# STM32G544 register map
File version: 2.0.0
CPU: CM33 r0p4, little endian, MPU, FPU, 4 interrupt priority bits
Registers are 32-bit, read-write, reset 0x0 unless marked. A register's access mark holds for its fields unless they carry their own. Offsets are from the block's base; [hi:lo] are bit positions; lines under a group give offsets from that group; {n}, {i} and the like mark numbered series.

## I3C1 (part 2 of 2) — Improved inter-integrated circuit
Base 0x40005C00
Same registers: I3C1_S 0x50005C00
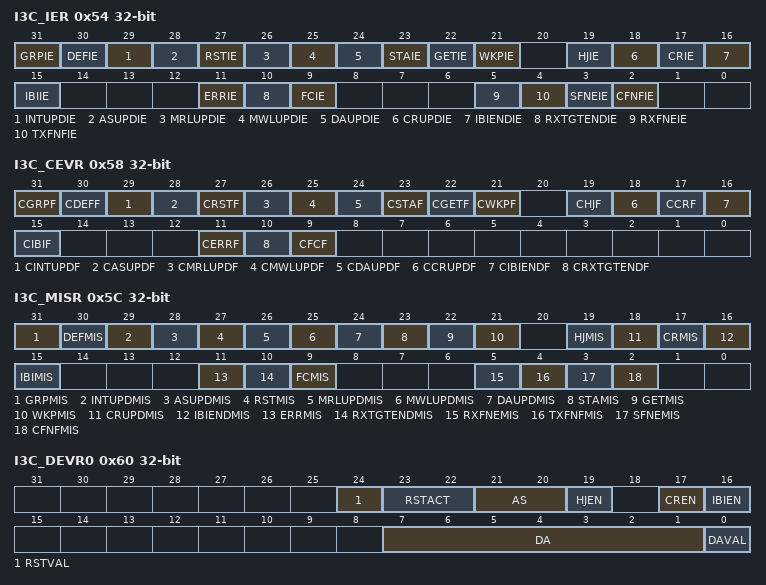
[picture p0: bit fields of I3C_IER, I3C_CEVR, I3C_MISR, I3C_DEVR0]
0x54 I3C_IER — I3C interrupt enable register
  [all] fields
    0=interrupt disabled; 1=interrupt enabled
  [31] GRPIE — DEFGRPA CCC interrupt enable (when the I3C is acting as target)
  [30] DEFIE — DEFTGTS CCC interrupt enable (when the I3C is acting as target)
  [29] INTUPDIE — ENEC/DISEC CCC interrupt enable (when the I3C is acting as target)
  [28] ASUPDIE — ENTASx CCC interrupt enable (when the I3C is acting as target)
  [27] RSTIE — reset pattern interrupt enable (when the I3C is acting as target)
  [26] MRLUPDIE — SETMRL CCC interrupt enable (when the I3C is acting as target)
  [25] MWLUPDIE — SETMWL CCC interrupt enable (when the I3C is acting as target)
  [24] DAUPDIE — ENTDAA/RSTDAA/SETNEWDA CCC interrupt enable (when the I3C is acting as target)
  [23] STAIE — GETSTATUS CCC interrupt enable (when the I3C is acting as target)
  [22] GETIE — GETxxx CCC interrupt enable (when the I3C is acting as target)
  [21] WKPIE — wakeup interrupt enable (when the I3C is acting as target)
  [19] HJIE — hot-join interrupt enable (when the I3C is acting as controller)
  [18] CRUPDIE — controller-role update interrupt enable (when the I3C is acting as target)
  [17] CRIE — controller-role request interrupt enable (when the I3C is acting as controller)
  [16] IBIENDIE — IBI end interrupt enable (when the I3C is acting as target)
  [15] IBIIE — IBI request interrupt enable (when the I3C is acting as controller)
  [11] ERRIE — error interrupt enable (whatever the I3C is acting as controller/target)
  [10] RXTGTENDIE — target-initiated read end interrupt enable (when the I3C is acting as controller)
  [9] FCIE — frame complete interrupt enable (whatever the I3C is acting as controller/target)
  [5] RXFNEIE — RX-FIFO not empty interrupt enable (whatever the I3C is acting as controller/target)
  [4] TXFNFIE — TX-FIFO not full interrupt enable (whatever the I3C is acting as controller/target)
  [3] SFNEIE — S-FIFO not empty interrupt enable (whatever the I3C is acting as controller/target)
  [2] CFNFIE — C-FIFO not full interrupt enable (whatever the I3C is acting as controller/target)
0x58 I3C_CEVR wo — I3C clear event register
  [31] CGRPF — clear DEFGRPA CCC flag (when the I3C is acting as target)
    0=no effect; 1=clear I3C_EVR.GRPF
  [30] CDEFF — clear DEFTGTS CCC flag (when the I3C is acting as target)
    0=no effect; 1=clear I3C_EVR.DEFF
  [29] CINTUPDF — clear ENEC/DISEC CCC flag (when the I3C is acting as target)
    0=no effect; 1=clear I3C_EVR.CINTUPDF
  [28] CASUPDF — clear ENTASx CCC flag (when the I3C is acting as target)
    0=no effect; 1=clear I3C_EVR.ASUPDF
  [27] CRSTF — clear reset pattern flag (when the I3C is acting as target)
    0=no effect; 1=clear I3C_EVR.RSTF
  [26] CMRLUPDF — clear SETMRL CCC flag (when the I3C is acting as target)
    0=no effect; 1=clear I3C_EVR.MRLUPDF
  [25] CMWLUPDF — clear SETMWL CCC flag (when the I3C is acting as target)
    0=no effect; 1=clear I3C_EVR.MWLUPDF
  [24] CDAUPDF — clear ENTDAA/RSTDAA/SETNEWDA CCC flag (when the I3C is acting as target)
    0=no effect; 1=clear I3C_EVR.DAUPDF
  [23] CSTAF — clear GETSTATUS CCC flag (when the I3C is acting as target)
    0=no effect; 1=clear I3C_EVR.STAF
  [22] CGETF — clear GETxxx CCC flag (when the I3C is acting as target)
    0=no effect; 1=clear I3C_EVR.GETF
  [21] CWKPF — clear wakeup flag (when the I3C is acting as target)
    0=no effect; 1=clear I3C_EVR.WKPF
  [19] CHJF — clear hot-join flag (when the I3C is acting as controller)
    0=no effect; 1=clear I3C_EVR.HJF
  [18] CCRUPDF — clear controller-role update flag (when the I3C is acting as target)
    0=no effect; 1=clear I3C_EVR.CRUPDF
  [17] CCRF — clear controller-role request flag (when the I3C is acting as controller)
    0=no effect; 1=clear I3C_EVR.CRF
  [16] CIBIENDF — clear IBI end flag (when the I3C is acting as target)
    0=no effect; 1=clear I3C_EVR.IBIENDF
  [15] CIBIF — clear IBI request flag (when the I3C is acting as controller)
    0=no effect; 1=clear I3C_EVR.IBIF
  [11] CERRF — clear error flag (whatever the I3C is acting as controller/target)
    0=no effect; 1=clear I3C_EVR.ERRF
  [10] CRXTGTENDF — clear target-initiated read end flag (when the I3C is acting as controller)
    0=no effect; 1=clear I3C_EVR.RXTGTENDF
  [9] CFCF — clear frame complete flag (whatever the I3C is acting as controller/target)
    0=no effect; 1=clear I3C_EVR.FCF
0x5C I3C_MISR ro — I3C masked interrupt status register
  [31] GRPMIS — DEFGRPA CCC masked interrupt status (when the I3C acts as target)
  [30] DEFMIS — DEFTGTS CCC masked interrupt status (when the I3C acts as target)
  [29] INTUPDMIS — ENEC/DISEC CCC masked interrupt status (when the I3C acts as target)
  [28] ASUPDMIS — ENTASx CCC masked interrupt status (when the I3C acts as target)
  [27] RSTMIS — reset pattern masked interrupt status (when the I3C acts as target)
  [26] MRLUPDMIS — SETMRL CCC masked interrupt status (when the I3C acts as target)
  [25] MWLUPDMIS — SETMWL CCC masked interrupt status (when the I3C acts as target)
  [24] DAUPDMIS — ENTDAA/RSTDAA/SETNEWDA CCC masked interrupt status (when the I3C acts as target)
  [23] STAMIS — format 1 GETSTATUS CCC masked interrupt status (when the I3C acts as target)
  [22] GETMIS — GETxxx CCC masked interrupt status, except GETSTATUS of format 1 (when the I3C acts as target)
  [21] WKPMIS — Wake-up/missed start masked interrupt status (when the I3C acts as target)
  [19] HJMIS — Hot-join masked interrupt status (when the I3C acts as controller)
  [18] CRUPDMIS — Controller-role update masked interrupt status (when the I3C acts as target)
  [17] CRMIS — Controller-role request masked interrupt status (when the I3C acts as controller)
  [16] IBIENDMIS — IBI end masked interrupt status (when the I3C acts as target)
  [15] IBIMIS — IBI request masked interrupt status (when the I3C acts as controller)
  [11] ERRMIS — error masked interrupt status (whatever the I3C acts as controller/target)
  [10] RXTGTENDMIS — target-initiated read end masked interrupt status (when the I3C acts as controller)
  [9] FCMIS — frame complete masked interrupt status (whatever the I3C acts as controller/target)
  [5] RXFNEMIS — RX-FIFO not empty masked interrupt status (whatever the I3C acts as controller/target)
  [4] TXFNFMIS — TX-FIFO not full masked interrupt status (whatever the I3C acts as controller/target)
  [3] SFNEMIS — S-FIFO not empty masked interrupt status (when the I3C acts as controller)
  [2] CFNFMIS — C-FIFO not full masked interrupt status (when the I3C acts as controller)
0x60 I3C_DEVR0 — I3C own device characteristics register
  [24] RSTVAL ro — reset action is valid (when the I3C is acting as target) This read bit is asserted by hardware to indicate that the RTSACT[1:0] field has been updated on the reception of a broadcast or direct write RSTACT CCC (target reset action) and is valid. This field is cleared by hardware when the target receives a frame start. If RSTVAL=1: when the RSTF is asserted (and/or the corresponding interrupt if enabled), I3C_DEVR0.RSTACT[1:0] dictates the reset action to be performed by the software if any. If RSTVAL=0: when the RSTF is asserted (and/or the corresponding interrupt if enabled), the software should issue an I3C reset after a first detected reset pattern, and a system reset on the second one.
  [23:22] RSTACT ro — reset action/level on received reset pattern (when the I3C is acting as target) This read field is used by hardware on the reception of a direct read RSTACT CCC in order to return the corresponding data byte on the I3C bus. This read field is updated by hardware on the reception of a broadcast or direct write RSTACT CCC (target reset action).
    0=no reset action; 1=first level of reset: the application software should either:; 2=second level of reset: the application software should issue a warm reset, also known as; 3=no reset action
  [21:20] AS ro — activity state (when the I3C is acting as target) This read field is updated by hardware on the reception of a ENTASx CCC (enter activity state, with x=0-3):
    {v}=activity state {v} (v=0..3)
  [19] HJEN — hot-join request enable (when the I3C is acting as target) This field is initially written by software when I3C_CFGR.EN=0, and is updated by hardware on the reception of DISEC CCC with DISHJ=1 (i.e. cleared) and the reception of ENEC CCC with ENHJ=1 (i.e. set).
    0=hot-join request disabled; 1=hot-join request enabled
  [17] CREN — controller-role request enable (when the I3C is acting as target) This field is initially written by software when I3C_CFGR.EN=0, and is updated by hardware on the reception of DISEC CCC with DISCR=1 (i.e. cleared) and the reception of ENEC CCC with ENCR=1 (i.e. set).
    0=controller-role request disabled; 1=controller-role request enabled
  [16] IBIEN — IBI request enable (when the I3C is acting as target) This field is initially written by software when I3C_CFGR.EN=0, and is updated by hardware on the reception of DISEC CCC with DISINT=1 (i.e. cleared) and the reception of ENEC CCC with ENINT=1 (i.e. set).
    0=IBI request disabled; 1=IBI request enabled
  [7:1] DA — 7-bit dynamic address When the I3C is acting as controller, this field can be written by software, for defining its own dynamic address. When the I3C is acting as target, this field is updated by hardware on the reception of either the broadcast ENTDAA CCC or the direct SETNEWDA CCC.
  [0] DAVAL — dynamic address is valid (when the I3C is acting as target) When the I3C is acting as controller, this field can be written by software, for validating its own dynamic address, for example before a controller-role hand-off. When the I3C is acting as target, this field is asserted by hardware on the acknowledge of the broadcast ENTDAA CCC or the direct SETNEWDA CCC, and this field is cleared by hardware on the acknowledge of the broadcast RSTDAA CCC.
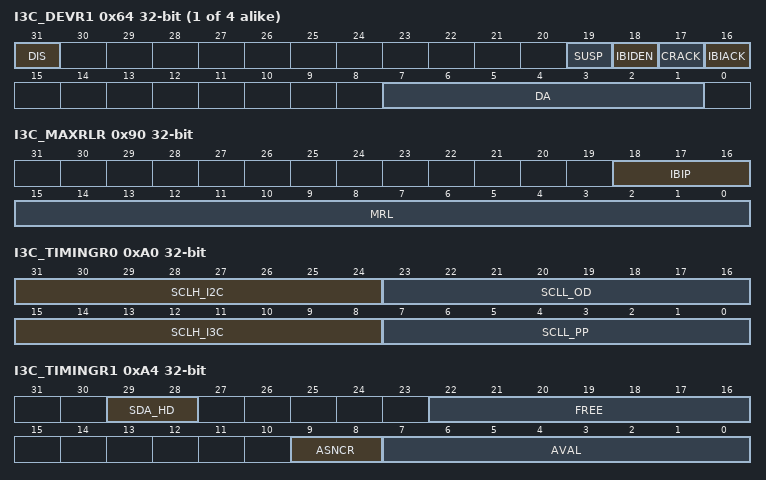
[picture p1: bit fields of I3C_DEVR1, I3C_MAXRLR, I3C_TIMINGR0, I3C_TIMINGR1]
{0x60+4i} I3C_DEVR{i} (i=1..4) — I3C device {i} characteristics register
  [31] DIS ro — DA[6:0] write disabled (when the I3C is acting as controller) When the I3C is acting as controller, once that software set IBIACK=1 or CRACK=1, this read bit is set by hardware (i.e. DIS=1) to lock the configured DA[6:0] and IBIDEN values. Then, to be able to next modify DA[6:0] or IBIDEN, the software must wait for this field DIS to be de-asserted by hardware (i.e. polling on DIS=0) before modifying these two assigned values to the target x. Indeed, the target may be requesting an IBI or a controller-role meanwhile the controller intends to modify DA[6:0] or IBIDEN.
    0=write to I3C_DEVRx.DA[7:0] and to I3C_DEVRx.IBIDEN is allowed; 1=write I3C_DEVRx.DA[7:0] and to I3C_DEVRx.IBIDEN is disabled/locked
  [19] SUSP — suspend/stop I3C transfer on received IBI (when the I3C is acting as controller) When the I3C is acting as controller, this bit is used to receive an IBI from target x with pending read notification feature (i.e. with received MDB[7:5]=3'b101). If this bit is set, when an IBI is received (i.e. I3C_EVR.IBIF=1), a Stop is emitted on the I3C bus and the C-FIFO is automatically flushed by hardware; to avoid a next private read communication issue if a previous private read message to the target x was stored in the C-FIFO.
    0=I3C transfer is not stopped and C-FIFO is not flushed; 1=I3C transfer is stopped and C-FIFO is flushed on a received IBI request from target x
  [18] IBIDEN — IBI data enable (when the I3C is acting as controller) When the I3C is acting as controller, this bit should be written by software to store the BCR[2] bit as received from the target x during broadcast ENTDAA or direct GETBCR CCC via the received I3C_RDR. Writing to this field has no impact when the read field I3C_DEVRx.DIS=1.
    0=no data byte follows the acknowledged IBI from target x; 1=the mandatory data byte MDB[7:0] follows the acknowledged IBI from target x
  [17] CRACK — controller-role request acknowledge (when the I3C is acting as controller) When the I3C is acting as controller, this bit is written by software to define the acknowledge policy to be applied on the I3C bus on the reception of a controller-role request from target x: After the NACK, the message continues as initially programmed (the target is aware of the NACK and can emit another controller-role request later on) - The field DIS is asserted by hardware to protect DA[6:0] from being modified by software meanwhile the hardware can store internally the current DA[6:0] into the kernel clock domain. - After the ACK, the message continues as initially programmed. The software is notified by the controller-role request flag (i.e. I3C_EVR.CRF=1) and/or the corresponding interrupt if enabled; For effectively granting the controller-role to the requesting secondary controller, software should issue a GETACCCR (formerly known as GETACCMST), followed by a STOP. - Independently of CRACK configuration for this or other devices, further controller-role request(s) are NACKed until controller-role request flag (i.e. I3C_EVR.CRF) and IBI flag (i.e. I3C_EVR.IBIF) are both cleared.
    0=a controller-role request from target x is to be NACKed; 1=a controller-role request (with 7-bit dynamic address DA[6:0]) from target x is to be ACKed
  [16] IBIACK — IBI request acknowledge (when the I3C is acting as controller) When the I3C is acting as controller, this bit is written by software to define the acknowledge policy to be applied on the I3C bus on the reception of a IBI request from target x: - After the NACK, the message continues as initially programmed (the target is aware of the NACK and can emit another IBI request later on) - The field DIS is asserted by hardware to protect DA[6:0] from being modified by software meanwhile the hardware can store internally the current DA[6:0] into the kernel clock domain. - After the ACK, the controller logs the IBI payload data, if any, depending on I3C_DEVRx.IBIDEN. - The software is notified by the IBI flag (i.e. I3C_EVR.IBIF=1) and/or the corresponding interrupt if enabled; - Independently from IBIACK configuration for this or other devices, further IBI request(s) are NACKed until IBI request flag (i.e. I3C_EVR.IBIF) and controller-role request flag (i.e. I3C_EVR.CRF) are both cleared.
    0=an IBI request from target x is to be NACKed; 1=an IBI request (with 7-bit dynamic address DA[6:0]) from target x is to be ACKed
  [7:1] DA — assigned I3C dynamic address to target x (when the I3C is acting as controller) When the I3C is acting as controller, this field should be written by software to store the 7-bit dynamic address that the controller sends via a broadcast ENTDAA or a direct SETNEWDA CCC which has been acknowledged by the target x. Writing to this field has no impact when the read field I3C_DEVRx.DIS=1.
0x90 I3C_MAXRLR — I3C maximum read length register
  [18:16] IBIP — IBI payload data size, in bytes (when I3C is acting as target) This field is initially written by software when I3C_CFGR.EN=0 to set the number of data bytes to be sent to the controller after an IBI request has been acknowledged.This field may be updated by hardware on the reception of SETMRL command (which potentially also updated IBIP[2:0]). Software is notified of a MRL update by the I3C_EVR.MRLUPF and the corresponding interrupt if enabled. others: same as 100
    0=null payload data size (only allowed when IC3_BCR.BCR2=0); 1=1 byte (i.e. mandatory data byte MDB[7:0]; 2=2 bytes (including first MDB[7:0]); 3=3 bytes (including first MDB[7:0]); 4=4 bytes (including first MDB[7:0])
  [15:0] MRL — maximum data read length (when I3C is acting as target) This field is initially written by software when I3C_CFGR.EN=0 and updated by hardware on the reception of SETMRL command (with potentially also updated IBIP[2:0]). Software is notified of a MRL update by the I3C_EVR.MRLUPF and the corresponding interrupt if enabled. This field is used by hardware to return the value on the I3C bus when the target receives a GETMRL CCC.
0x94 I3C_MAXWLR — I3C maximum write length register
  [15:0] MWL — maximum data write length (when I3C is acting as target) This field is initially written by software when I3C_CFGR.EN=0 and updated by hardware on the reception of SETMWL command. Software is notified of a MWL update by the I3C_EVR.MWLUPF and the corresponding interrupt if enabled. This field is used by hardware to return the value on the I3C bus when the target receives a GETMWL CCC.
0xA0 I3C_TIMINGR0 — I3C timing register 0
  [31:24] SCLH_I2C — SCL high duration, used for legacy I2C commands, in number of kernel clocks cycles: tSCLH_I2C = (SCLH_I2C + 1) x tI3CCLK SCLH_I2C is used to generate tHIGH (I2C) timing.
  [23:16] SCLL_OD — SCL low duration in open-drain phases, used for legacy I2C commands and for I3C open-drain phases (address header phase following a START, not a Repeated START), in number of kernel clocks cycles: tSCLL_OD = (SCLL_OD + 1) x tI3CCLK SCLL_OD is used to generate both tLOW (I2C) and tLOW_OD timings (max. of the two).
  [15:8] SCLH_I3C — SCL high duration, used for I3C messages (both in push-pull and open-drain phases), in number of kernel clocks cycles: tSCLH_I3C = (SCLH_I3C + 1) x tI3CCLK SCLH_I3C is used to generate both tHIGH (I3C) and tHIGH_MIXED timings.
  [7:0] SCLL_PP — SCL low duration in I3C push-pull phases, in number of kernel clocks cycles: tSCLL_PP = (SCLL_PP + 1) x tI3CCLK SCLL_PP is used to generate tLOW (I3C) timing.
0xA4 I3C_TIMINGR1 — I3C timing register 1
  [29:28] SDA_HD — SDA hold time (when the I3C acts as controller), in number of kernel clocks cycles (refer to MIPI timing SDA hold time in push-pull tless thansub>HD_PPless than/sub>):
  [22:16] FREE — number of kernel clocks cycles that is used to set some MIPI timings like bus free condition time (when the I3C is acting as controller)
  [9:8] ASNCR — activity state of the new controller (when I3C is acting as active- controller) This field indicates the time to wait before being accessed as new target, refer to the other field AVAL[7:0]. This field can be modified only when the I3C is acting as controller.
  [7:0] AVAL — number of kernel clock cycles, that is used whatever I3C is acting as controller or target, to set the following MIPI I3C timings, like bus available condition time: When the I3C is acting as target: for bus available condition time: it must wait for (bus available condition) time to be elapsed after a stop and before issuing a start request for an IBI or a controller-role request (i.e. bus free condition is sustained for at least tAVAL). refer to MIPI timing tAVAL = 1 s. This timing is defined by: tAVAL = (AVAL[7:0] + 2) x tI3CCLK for bus idle condition time: it must wait for (bus idle condition) time to be elapsed after that both SDA and SCL are continuously high and stable before issuing a hot-join event. Refer to MIPI v1.1 timing tIDLE = 200 s . This timing is defined by: tIDLE = (AVAL[7:0] + 2) x 200 x tI3CCLK When the I3C is acting as controller, it can not stall the clock beyond a maximum stall time (i.e. stall the SCL clock low), as follows: on first bit of assigned address during dynamic address assignment: it can not stall the clock beyond the MIPI timing tSTALLDAA = 15 ms. This timing is defined by: tSTALLDAA = (AVAL[7:0] + 1) x 15000 x tI3CCLK on ACK/NACK phase of I3C/I2C transfer, on parity bit of write data transfer, on transition bit of I3C read transfer: it can not stall the clock beyond the MIPI timing tSTALL = 100 s. This timing is defined by: tSTALL = (AVAL[7:0] + 1) x 100 x tI3CCLK Whatever the I3C is acting as controller or as (controller-capable) target, during a controller-role hand-off procedure: The new controller must wait for a time (refer to MIPI timing tNEWCRLock) before pulling SDA low (i.e. issuing a start). And the active controller must wait for the same time while monitoring new controller and before testing the new controller by pulling SDA low. This time to wait is dependent on the defined I3C_TIMINGR1.ANSCR[1:0], as follows: If ASNCR[1:0]=00: tNEWCRLock = (AVAL[7:0] + 1) x tI3CCLK If ASNCR[1:0]=01: tNEWCRLock = (AVAL[7:0] + 1) x 100 x tI3CCLK If ASNCR[1:0]=10: tNEWCRLock = (AVAL[7:0] + 1) x 2000 x tI3CCLK If ASNCR[1:0]=11: tNEWCRLock = (AVAL[7:0] + 1) x 50000 x tI3CCLK
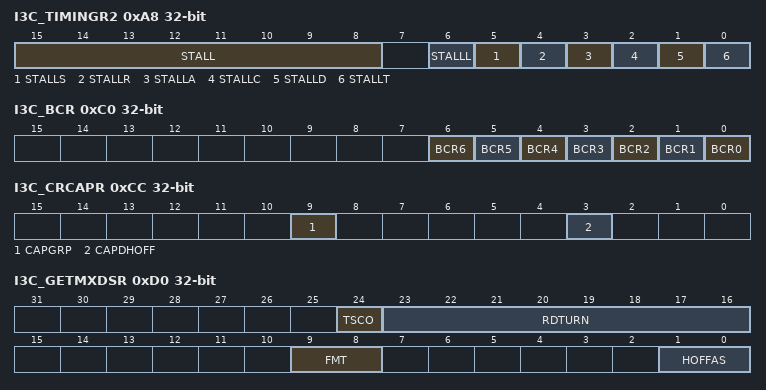
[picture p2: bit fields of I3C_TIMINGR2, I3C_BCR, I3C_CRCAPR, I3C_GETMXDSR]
0xA8 I3C_TIMINGR2 — I3C timing register 2
  [15:8] STALL — controller clock stall time, in number of kernel clock cycles tSCLL_STALL = STALL x tI3CCLK
  [6] STALLL — Controller clock stall enable in the address ACK/NACK phase (before the ninth bit) of a legacy I2C read/write message.
    0=no stall; 1=stall enabled
  [5] STALLS — Controller clock stall enable in the data ACK/NACK phase of a legacy I2C write message.
    0=no stall; 1=stall enabled
  [4] STALLR — Controller clock stall enable in the data ACK/NACK phase of a legacy I2C read message.
    0=no stall; 1=stall enabled
  [3] STALLA — controller clock stall enable on ACK phase The SCL is stalled (during tSCLL_STALLas defined by STALL) in the address ACK/NACK phase (before 9th bit). This allows the target to prepare data or the controller to respond to target interrupt.
    0=no stall; 1=stall enabled
  [2] STALLC — Controller clock stall enable on PAR phase of CCC
    0=no stall; 1=stall enabled
  [1] STALLD — Controller clock stall enable on PAR phase of Data
    0=no stall; 1=stall enabled
  [0] STALLT — Controller clock stall on T-bit phase of Data enable The SCL is stalled during STALL x tSCLL_PP in the T-bit phase (before 9th bit). This allows the target to prepare data to be sent.
    0=no stall; 1=stall enabled
0xC0 I3C_BCR — I3C bus characteristics register
  [6] BCR6 — controller capable
    0=I3C target (no controller capable); 1=I3C controller capable
  [5] BCR5 — Advanced capabilities
    0=I3C no advanced controller capable; 1=I3C advanced capabilities
  [4] BCR4 — Virtual target support
    0=Virtual target unsupported; 1=Virtual target support
  [3] BCR3 — Offline capable
    0=Offline uncapable; 1=Offline capable
  [2] BCR2 — in-band interrupt (IBI) payload
    0=no data byte follows the accepted IBI; 1=at least one mandatory data byte follows the accepted IBI (and at most 4 data bytes)
  [1] BCR1 — IBI Request capable
    0=IBI Request uncapable; 1=IBI Request
  [0] BCR0 — max data speed limitation
    0=no limitation; 1=limitation, as described by I3C_GETMXDSR
0xC4 I3C_DCR — I3C device characteristics register
  [7:0] DCR — device characteristics ID others: ID to describe the type of the I3C sensor/device Note: The latest MIPI DCR ID assignments are available at: https://www.mipi.org/MIPI_I3C_device_characteristics_register
    0=generic device (for v1.0 devices)
0xC8 I3C_GETCAPR — I3C get capability register
  [14] CAPPEND — IBI MDB support for pending read notification This bit is written by software during bus initialization (i.e. I3C_CFGR.EN=0) and indicates the support (or not) of the pending read notification via the IBI MDB[7:0] value. This bit is used to return the GETCAP3 byte in response to the GETCAPS CCC format 1.
    0=this I3C when acting as target sends an IBI request without a mandatory data byte value indicating a pending read notification; 1=this I3C when acting as target sends an IBI request with a mandatory data byte value (i.e. a MDB[7:5]=101) indicating a pending read notification
0xCC I3C_CRCAPR — I3C controller-role capability register
  [9] CAPGRP — group management support (when acting as controller) This bit is written by software during bus initialization (i.e. I3C_CFGR.EN=0) and indicates if the I3C is able to support group management when it acts as a controller (after controller-role hand-off) via emitted DEFGRPA, RSTGRPA, and SETGRPA CCC. This bit is used to return the CRCAP1 byte in response to the GETCAPS CCC format 2.
    0=this I3C does not support group address capabilities; 1=this I3C supports group address capabilities (when becoming controller)
  [3] CAPDHOFF — delayed controller-role hand-off This bit is written by software during bus initialization (i.e. I3C_CFGR.EN=0) and indicates if this target I3C may need additional time to process a controller-role hand-off requested by the current controller. This bit is used to return the CRCAP2 byte in response to the GETCAPS CCC format 2.
    0=this I3C does not needs additional time to process a controller-role hand-off; 1=this I3C needs additional time to process a controller-role hand-off
0xD0 I3C_GETMXDSR — I3C get capability register
  [24] TSCO — clock-to-data turnaround time (tSCO) This bit is written by software during bus initialization (i.e. I3C_CFGR.EN=0) and is used to specify the clock-to-data turnaround time tSCO (vs the value of 12 ns). This bit is used by the hardware in response to the GETMXDS CCC to return the encoded clock-to-data turnaround time via the returned MaxRd[5:3] bits.
    0=tSCO = 12 ns; 1=tSCO 12 ns (and refer to the datasheet for more details)
  [23:16] RDTURN — programmed byte of the 3-byte MaxRdTurn (maximum read turnaround byte) This bit is written by software during bus initialization (i.e. I3C_CFGR.EN=0) and writes the value of the selected byte (via the FMT[1:0] field) of the 3-byte MaxRdTurn which is returned in response to the GETMXDS CCC format 2 to encode the maximum read turnaround time.
  [9:8] FMT — GETMXDS CCC format This field is written by software during bus initialization (i.e. I3C_CFGR.EN=0) and indicates how is returned the GETMXDS format 1 (without MaxRdTurn) and format 2 (with MaxRdTurn). This bit is used to return the 2-byte format 1 (MaxWr, MaxRd) or 5-byte format 2 (MaxWr, MaxRd, 3-byte MaxRdTurn) byte in response to the GETCAPS CCC. - 3-byte MaxRdTurn is returned with MSB=0, middle byte=0 and LSB=RDTURN[7:0]. - Max read turnaround time is less than 256 s. - 3-byte MaxRdTurn is returned with MSB=0, middle byte=RDTURN[7:0] and LSB=0. - Max read turnaround time is between 256 s and 65535 s - 3-byte MaxRdTurn is returned with MSB=RDTURN[7:0], middle byte=0 and LSB=0. - Max read turnaround time is between 65535 s and 16 s.
    0=format 1 (2 bytes with MaxWr with no defining byte, MaxRd); 1=format 2: (5 bytes with MaxWr with no defining byte, MaxRd, MaxRdTurn); 2=format 2 (5 bytes with MaxWr with no defining byte, MaxRd, and middle byte of MaxRdTurn); 3=format 2 (5 bytes with MaxWr with no defining byte, MaxRd, MSB of MaxRdTurn)
  [1:0] HOFFAS — controller hand-off activity state This bit is written by software during bus initialization (i.e. I3C_CFGR.EN=0) and indicates in which initial activity state the (other) current controller should expect the I3C bus after a controller-role hand-off to this controller-capable I3C, when returning the defining byte CRHDLY (0x91) to a GETMXDS CCC. This 2-bit field is used to return the CRHDLY1 byte in response to the GETCAPS CCC format 3, in order to state which is the activity state of this I3C when becoming controller after a controller-role hand-off, and consequently the time the former controller should wait before testing this I3C to be confirmed its ownership.
    0=activity state 0 is the initial activity state of this I3C before and when becoming controller; 1=activity state 1 is the initial activity state of this I3C when becoming controller; 2=activity state 2 is the initial activity state of this I3C when becoming controller; 3=activity state 3 is the initial activity state of this I3C when becoming controller
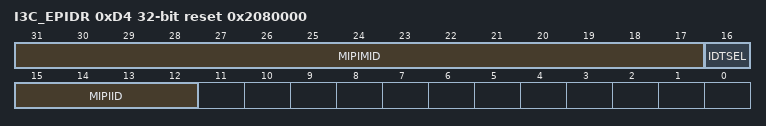
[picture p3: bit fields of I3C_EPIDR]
0xD4 I3C_EPIDR reset 0x2080000 — I3C extended provisioned ID register
  [31:17] MIPIMID ro — 15-bit MIPI manufacturer ID This read field is the 15-bit STMicroelectronics MIPI ID i.e. 0x0104. This field represents the bits[47:33] of the 48-bit provisioned ID.
  [16] IDTSEL ro — provisioned ID type selector This field is set as 0 i.e. vendor fixed value. This field represents the bit[32] of the 48-bit provisioned ID. Note: The bits[31:16] of the provisioned ID may be 0.
  [15:12] MIPIID — 4-bit MIPI Instance ID This field is written by software to set and identify individually each instance of this I3C IP with a specific number on a single I3C bus. This field represents the bits[15:12] of the 48-bit provisioned ID. Note: The bits[11:0] of the provisioned ID may be 0.
